AUTOSAR XML (schema 4-2-2)
standard types defined: boolean, float32, float64, sint16, sint32, sint8, uint16, uint32, uint8
package /PortInterfaces
  sender receiver interface Current_SRI
    data DEP_Current: type=Appl_SINT8
  sender receiver interface Debug_SRI
    data DEP_Debug_SINT8: type=Appl_SINT8
    data DEP_Debug_SINT16: type=Appl_SINT16
    data DEP_Debug_SINT32: type=Appl_SINT32
  sender receiver interface Torque_SRI
    data DEP_Torque: type=Appl_UINT16
package /Pkg_ApplicationPrimitiveDataType
  4 x app type, all with category=VALUE:
    Appl_SINT8
    Appl_SINT16
    Appl_SINT32
    Appl_UINT16
  application record data type ApplicationRecordDataType_0: category=STRUCTURE
    application record element ApplicationRecordElement_0: category=VALUE
package /Pkg_ImplementationDataTypes
  5 x impl type, all with category=TYPE_REFERENCE:
    Impl_SINT8: implementation-data-type=sint8
    Impl_SINT16: implementation-data-type=sint16
    Impl_SINT32: implementation-data-type=sint32
    Impl_UINT16: implementation-data-type=uint16
    Impl_UINT32: implementation-data-type=uint32
package /WiperControl_100us
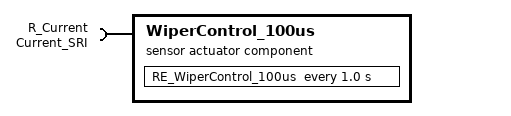
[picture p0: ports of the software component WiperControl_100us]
  sensor actuator sw component type WiperControl_100us
    require port R_Current: required-interface=Current_SRI
    behavior IB_WiperControl_100us: data-type-mapping=DTMS_WiperControl_100us
      timing event TimingEvent_100us: start-on-event=RE_WiperControl_100us, period=1.0E-4
      data write completed event DataWriteCompletedEvent_0: start-on-event=RE_WiperControl_100us, event-source=DataWriteAccess_VariableAccess_0
      runnable RE_WiperControl_100us: symbol=RE_WiperControl_100us_func
        data-read-access:
          access DataReadAccess_0: accessed-variable=R_Current.DEP_Current
        data-receive-point-by-arguments:
          access DataReceivePointByArguments_VariableAccess_0
        data-receive-point-by-values:
          access DataReceivePointByValues_VariableAccess_0: accessed-variable=R_Current.DEP_Current
        data-send-points:
          access DataSendPoints_VariableAccess_0
        data-write-access:
          access DataWriteAccess_VariableAccess_0
  nv data interface NvDataInterface_0
    nv-datas:
      data NvDatas_VariableDataPrototype_0: type=Appl_SINT16
package /WiperControl_100us/DataTypeMappingSets
  data type mapping set DTMS_WiperControl_100us: data-type-map{application-data-type=Appl_SINT8, implementation-data-type=Impl_SINT8}
package /WiperControl_2ms
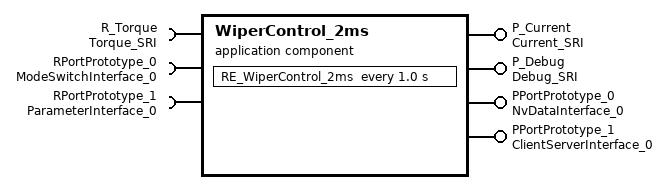
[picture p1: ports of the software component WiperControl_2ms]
  application sw component type WiperControl_2ms
    provide port P_Current: sender-annotation{annotation-origin=origin1, computed=false, data-element=DEP_Current, limit-kind=MAX, processing-kind=FILTERED}, provided-interface=Current_SRI
    provide port P_Debug: provided-interface=Debug_SRI
    require port R_Torque: required-interface=Torque_SRI
    provide port PPortPrototype_0: nv-data-port-annotation=NvDatas_VariableDataPrototype_0, provided-interface=NvDataInterface_0
    require port RPortPrototype_0: mode-port-annotation=ModeDeclarationGroupPrototype_0, required-interface=ModeSwitchInterface_0
    require port RPortPrototype_1: parameter-port-annotation=Parameters_ParameterDataPrototype_0, required-interface=ParameterInterface_0
    provide port PPortPrototype_1: client-server-annotation=ClientServerOperation_0, provided-interface=ClientServerInterface_0
    behavior IB_WiperControl_2ms: data-type-mapping=DTMS_WiperControl_2ms
      timing event TimingEvent_0: start-on-event=RE_WiperControl_2ms, period=1.0E-4
      operation invoked event OperationInvokedEvent_0
      data received event DataReceivedEvent_0
      runnable RE_WiperControl_2ms: symbol=WiperControl_2ms_RE_func
        data-receive-point-by-arguments:
          access DataReceivePointByArguments_0: accessed-variable=R_Torque.DEP_Torque
        data-send-points:
          access DataSendPoints_0: accessed-variable=P_Debug.DEP_Debug_SINT8
          access DataSendPoints_1: accessed-variable=P_Debug.DEP_Debug_SINT16
          access DataSendPoints_2: accessed-variable=P_Debug.DEP_Debug_SINT32
        data-write-access:
          access DataWriteAccess_0: accessed-variable=P_Current.DEP_Current
package /WiperControl_2ms/DataTypeMappingSets
  data type mapping set DTMS_WiperControl_2ms
    data-type-maps:
      application-data-type=Appl_UINT16, implementation-data-type=Impl_UINT16
      application-data-type=Appl_SINT32, implementation-data-type=Impl_SINT32
      application-data-type=Appl_SINT16, implementation-data-type=Impl_SINT16
      application-data-type=Appl_SINT8, implementation-data-type=Impl_SINT8
package /Debug
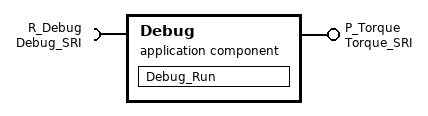
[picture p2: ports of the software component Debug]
  application sw component type Debug
    provide port P_Torque: sender-annotation{annotation-origin=ORIGIN, computed=true, data-element=DEP_Torque, limit-kind=MIN, processing-kind=FILTERED}, provided-interface=Torque_SRI
    require port R_Debug: receiver-annotation{computed=false, data-element=DEP_Debug_SINT8, limit-kind=MAX, processing-kind=RAW}, required-interface=Debug_SRI
    behavior Debug_IB: data-type-mapping=DTMS_Debug
      runnable Debug_Run: symbol=Debug_Run_func
        data-receive-point-by-values:
          access DataReceivePointByValues_0: accessed-variable=R_Debug.DEP_Debug_SINT8
          access DataReceivePointByValues_1: accessed-variable=R_Debug.DEP_Debug_SINT16
          access DataReceivePointByValues_2: accessed-variable=R_Debug.DEP_Debug_SINT32
        data-send-points:
          access DataSendPoints_0: accessed-variable=P_Torque.DEP_Torque
  mode switch interface ModeSwitchInterface_0
    mode group ModeDeclarationGroupPrototype_0
  parameter interface ParameterInterface_0
    parameter data prototype Parameters_ParameterDataPrototype_0: type=Appl_SINT16
  client server interface ClientServerInterface_0
    operation ClientServerOperation_0
      arg ArgumentDataPrototype_0: direction=IN, type=Appl_SINT16
package /Debug/DataTypeMappingSets
  data type mapping set DTMS_Debug
    data-type-maps:
      application-data-type=Appl_SINT16, implementation-data-type=Impl_SINT16
      application-data-type=Appl_SINT32, implementation-data-type=Impl_SINT32
      application-data-type=Appl_SINT8, implementation-data-type=Impl_SINT8
      application-data-type=Appl_UINT16, implementation-data-type=Impl_UINT16
package /AUTOSAR_PlatformTypes/ImplementationDataTypes  # AUTOSAR platform types
package /AUTOSAR_PlatformTypes/SwBaseTypes  # AUTOSAR platform types
package /AUTOSAR_PlatformTypes/DataConstraints  # AUTOSAR platform types
  range DataConstr_uint8: phys 0..255, raw 0..255
  range DataConstr_uint16: phys 0..65535, raw 0..65535
  range DataConstr_uint32: phys 0..4294967295, raw 0..4294967295
  range DataConstr_sint8: phys -128..127, raw -128..127
  range DataConstr_sint16: phys -32768..32767, raw -32768..32767
  range DataConstr_sint32: phys -2147483648..2147483647, raw -2147483648..2147483647
  range DataConstr_boolean: phys 0..1, raw 0..1
package /WiperControl_Composition
  composition sw component type WiperControl_SystemComposition
    component CPT_Debug: type=Debug
    component CPT_WiperControl_100us: type=WiperControl_100us
    component CPT_WiperControl_2ms: type=WiperControl_2ms
    connect CPT_WiperControl_2ms.P_Debug -> CPT_Debug.R_Debug
    connect CPT_Debug.P_Torque -> CPT_WiperControl_2ms.R_Torque
    connect CPT_WiperControl_2ms.P_Current -> CPT_WiperControl_100us.R_Current
